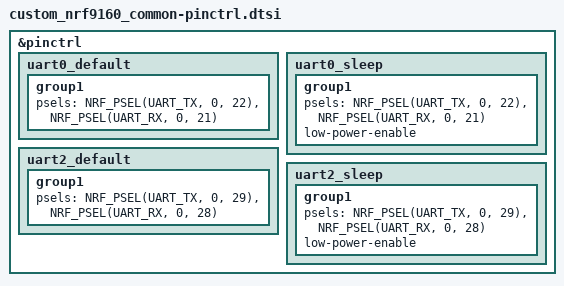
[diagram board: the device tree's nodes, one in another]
/*
 * Copyright (c) 2022 Nordic Semiconductor
 * SPDX-License-Identifier: Apache-2.0
 */

&pinctrl {
	uart0_default: uart0_default {
		group1 {
			psels = <NRF_PSEL(UART_TX, 0, 22)>,
				<NRF_PSEL(UART_RX, 0, 21)>;
		};
	};

	uart0_sleep: uart0_sleep {
		group1 {
			psels = <NRF_PSEL(UART_TX, 0, 22)>,
				<NRF_PSEL(UART_RX, 0, 21)>;
			low-power-enable;
		};
	};

	uart2_default: uart2_default {
		group1 {
			psels = <NRF_PSEL(UART_TX, 0, 29)>,
				<NRF_PSEL(UART_RX, 0, 28)>;
		};
	};

	uart2_sleep: uart2_sleep {
		group1 {
			psels = <NRF_PSEL(UART_TX, 0, 29)>,
				<NRF_PSEL(UART_RX, 0, 28)>;
			low-power-enable;
		};
	};
};
